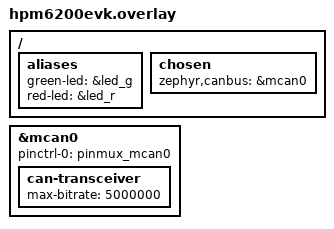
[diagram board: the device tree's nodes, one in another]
/*
 * Copyright 2025 HPMicro
 * SPDX-License-Identifier: Apache-2.0
 */

/ {
	aliases {
        green-led = &led_g;
		red-led = &led_r;
	};
	chosen {
        zephyr,canbus = &mcan0;
	};

};
&mcan0 {
    status = "okay";
    pinctrl-0 = <&pinmux_mcan0>;
    pinctrl-names = "default";
    	can-transceiver {
		max-bitrate = <5000000>;
	};
};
